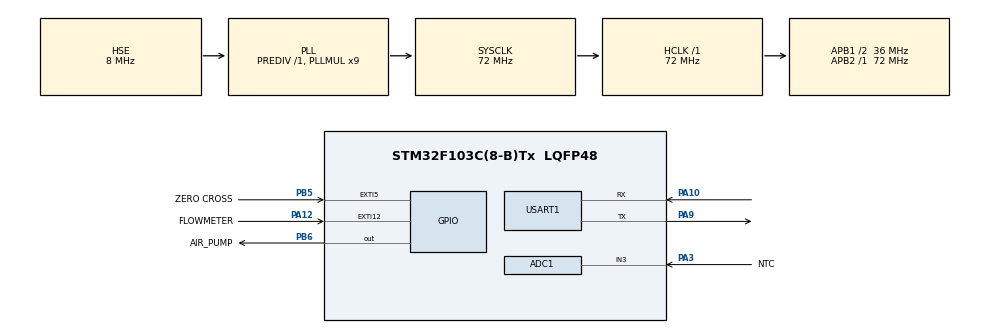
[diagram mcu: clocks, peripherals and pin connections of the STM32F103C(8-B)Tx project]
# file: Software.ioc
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ADC1.Channel-1\#ChannelRegularConversion=ADC_CHANNEL_3
ADC1.ContinuousConvMode=ENABLE
ADC1.NbrOfConversionFlag=1
ADC1.Rank-1\#ChannelRegularConversion=1
ADC1.SamplingTime-1\#ChannelRegularConversion=ADC_SAMPLETIME_1CYCLE_5
ADC1.master=1
Mcu.Family=STM32F1
Mcu.Name=STM32F103C(8-B)Tx
Mcu.Package=LQFP48
NVIC.ADC1_2_IRQn=true\:0\:0\:false\:false\:true\:true\:true
NVIC.EXTI9_5_IRQn=true\:0\:0\:false\:false\:true\:true\:true
NVIC.PriorityGroup=NVIC_PRIORITYGROUP_4
NVIC.TIM2_IRQn=true\:0\:0\:false\:false\:true\:true\:true
PA10.Mode=Asynchronous
PA10.Signal=USART1_RX
PA12.GPIO_Label=FLOWMETER
PA12.Signal=GPXTI12
PA13.Mode=Serial_Wire
PA13.Signal=SYS_JTMS-SWDIO
PA14.Mode=Serial_Wire
PA14.Signal=SYS_JTCK-SWCLK
PA3.GPIO_Label=NTC
PA3.Signal=ADCx_IN3
PA9.Mode=Asynchronous
PA9.Signal=USART1_TX
PB5.GPIO_Label=ZERO CROSS
PB5.Signal=GPXTI5
PB6.GPIO_Label=AIR_PUMP
PB6.Signal=GPIO_Output
PD0-OSC_IN.Mode=HSE-External-Oscillator
PD0-OSC_IN.Signal=RCC_OSC_IN
PD1-OSC_OUT.Mode=HSE-External-Oscillator
PD1-OSC_OUT.Signal=RCC_OSC_OUT
ProjectManager.HeapSize=0x200
ProjectManager.StackSize=0x400
ProjectManager.TargetToolchain=MDK-ARM V5.27
RCC.ADCPresc=RCC_ADCPCLK2_DIV6
RCC.AHBFreq_Value=72000000
RCC.APB1CLKDivider=RCC_HCLK_DIV2
RCC.APB1Freq_Value=36000000
RCC.APB1TimFreq_Value=72000000
RCC.APB2Freq_Value=72000000
RCC.APB2TimFreq_Value=72000000
RCC.HCLKFreq_Value=72000000
RCC.PLLMUL=RCC_PLL_MUL9
RCC.PLLSourceVirtual=RCC_PLLSOURCE_HSE
RCC.SYSCLKFreq_VALUE=72000000
RCC.SYSCLKSource=RCC_SYSCLKSOURCE_PLLCLK
RCC.USBFreq_Value=72000000
SH.ADCx_IN3.0=ADC1_IN3,IN3
TIM1.Period=65535
TIM1.Prescaler=7200-1 
TIM2.Period=1000
TIM2.Prescaler=7200
USART1.VirtualMode=VM_ASYNC
VP_TIM1_VS_ClockSourceINT.Mode=Internal
VP_TIM2_VS_ClockSourceINT.Mode=Internal
board=custom

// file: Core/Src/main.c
/* USER CODE BEGIN Header */
/**
  ******************************************************************************
  * @file           : main.c
  * @brief          : Main program body
  ******************************************************************************
  * @attention
  *
  * <h2><center>&copy; Copyright (c) 2022 STMicroelectronics.
  * All rights reserved.</center></h2>
  *
  * This software component is licensed by ST under BSD 3-Clause license,
  * the "License"; You may not use this file except in compliance with the
  * License. You may obtain a copy of the License at:
  *                        opensource.org/licenses/BSD-3-Clause
  *
  ******************************************************************************
  */
/* USER CODE END Header */
#include "main.h"

/* USER CODE BEGIN Includes */
#include "st7735.h"
#include "Control.h"
#include "NTC.h"
/* USER CODE END Includes */

ADC_HandleTypeDef hadc1;

TIM_HandleTypeDef htim1;
TIM_HandleTypeDef htim2;

UART_HandleTypeDef huart1;

void SystemClock_Config(void);
static void MX_GPIO_Init(void);
static void MX_ADC1_Init(void);
static void MX_TIM1_Init(void);
static void MX_TIM2_Init(void);
static void MX_USART1_UART_Init(void);

/* USER CODE BEGIN 0 */

uint32_t ADC_VAL;

//void HAL_ADC_ConvCpltCallback(ADC_HandleTypeDef* hadc)
//{
//   adc_val = HAL_ADC_GetValue(&hadc1);
//	 res = (adc_val * 47) / (4095 - adc_val);
//   HAL_ADC_Start_IT (&hadc1);
//}
/* USER CODE END 0 */

int main(void)
{

  /* MCU Configuration--------------------------------------------------------*/

  /* Reset of all peripherals, Initializes the Flash interface and the Systick. */
  HAL_Init();

  /* Configure the system clock */
  SystemClock_Config();

  /* Initialize all configured peripherals */
  MX_GPIO_Init();
  MX_ADC1_Init();
  MX_TIM1_Init();
  MX_TIM2_Init();
  MX_USART1_UART_Init();
  /* USER CODE BEGIN 2 */
	ST7735_Init();
	HAL_TIM_Base_Start(&htim1);
	HAL_TIM_Base_Start_IT(&htim2);
  HAL_ADC_Start_IT (&hadc1);
  /* USER CODE END 2 */

  /* Infinite loop */
  /* USER CODE BEGIN WHILE */
  while (1)
  {
		  HAL_GPIO_WritePin(GPIOB, GPIO_PIN_6, GPIO_PIN_SET);
      HAL_Delay(2000);
      // LED OFF
      HAL_GPIO_WritePin(GPIOB, GPIO_PIN_6, GPIO_PIN_RESET);
      HAL_Delay(2000);
    /* USER CODE END WHILE */

  }
}

void SystemClock_Config(void)
{
  RCC_OscInitTypeDef RCC_OscInitStruct = {0};
  RCC_ClkInitTypeDef RCC_ClkInitStruct = {0};
  RCC_PeriphCLKInitTypeDef PeriphClkInit = {0};

  /** Initializes the RCC Oscillators according to the specified parameters
  * in the RCC_OscInitTypeDef structure.
  */
  RCC_OscInitStruct.OscillatorType = RCC_OSCILLATORTYPE_HSE;
  RCC_OscInitStruct.HSEState = RCC_HSE_ON;
  RCC_OscInitStruct.HSEPredivValue = RCC_HSE_PREDIV_DIV1;
  RCC_OscInitStruct.HSIState = RCC_HSI_ON;
  RCC_OscInitStruct.PLL.PLLState = RCC_PLL_ON;
  RCC_OscInitStruct.PLL.PLLSource = RCC_PLLSOURCE_HSE;
  RCC_OscInitStruct.PLL.PLLMUL = RCC_PLL_MUL9;
  if (HAL_RCC_OscConfig(&RCC_OscInitStruct) != HAL_OK)
  {
    Error_Handler();
  }
  /** Initializes the CPU, AHB and APB buses clocks
  */
  RCC_ClkInitStruct.ClockType = RCC_CLOCKTYPE_HCLK|RCC_CLOCKTYPE_SYSCLK
                              |RCC_CLOCKTYPE_PCLK1|RCC_CLOCKTYPE_PCLK2;
  RCC_ClkInitStruct.SYSCLKSource = RCC_SYSCLKSOURCE_PLLCLK;
  RCC_ClkInitStruct.AHBCLKDivider = RCC_SYSCLK_DIV1;
  RCC_ClkInitStruct.APB1CLKDivider = RCC_HCLK_DIV2;
  RCC_ClkInitStruct.APB2CLKDivider = RCC_HCLK_DIV1;

  if (HAL_RCC_ClockConfig(&RCC_ClkInitStruct, FLASH_LATENCY_2) != HAL_OK)
  {
    Error_Handler();
  }
  PeriphClkInit.PeriphClockSelection = RCC_PERIPHCLK_ADC;
  PeriphClkInit.AdcClockSelection = RCC_ADCPCLK2_DIV6;
  if (HAL_RCCEx_PeriphCLKConfig(&PeriphClkInit) != HAL_OK)
  {
    Error_Handler();
  }
}

static void MX_ADC1_Init(void)
{

  ADC_ChannelConfTypeDef sConfig = {0};

  /** Common config
  */
  hadc1.Instance = ADC1;
  hadc1.Init.ScanConvMode = ADC_SCAN_DISABLE;
  hadc1.Init.ContinuousConvMode = ENABLE;
  hadc1.Init.DiscontinuousConvMode = DISABLE;
  hadc1.Init.ExternalTrigConv = ADC_SOFTWARE_START;
  hadc1.Init.DataAlign = ADC_DATAALIGN_RIGHT;
  hadc1.Init.NbrOfConversion = 1;
  if (HAL_ADC_Init(&hadc1) != HAL_OK)
  {
    Error_Handler();
  }
  /** Configure Regular Channel
  */
  sConfig.Channel = ADC_CHANNEL_3;
  sConfig.Rank = ADC_REGULAR_RANK_1;
  sConfig.SamplingTime = ADC_SAMPLETIME_1CYCLE_5;
  if (HAL_ADC_ConfigChannel(&hadc1, &sConfig) != HAL_OK)
  {
    Error_Handler();
  }

}

static void MX_TIM1_Init(void)
{

  TIM_ClockConfigTypeDef sClockSourceConfig = {0};
  TIM_MasterConfigTypeDef sMasterConfig = {0};

  htim1.Instance = TIM1;
  htim1.Init.Prescaler = 7200-1 ;
  htim1.Init.CounterMode = TIM_COUNTERMODE_UP;
  htim1.Init.Period = 65535;
  htim1.Init.ClockDivision = TIM_CLOCKDIVISION_DIV1;
  htim1.Init.RepetitionCounter = 0;
  htim1.Init.AutoReloadPreload = TIM_AUTORELOAD_PRELOAD_DISABLE;
  if (HAL_TIM_Base_Init(&htim1) != HAL_OK)
  {
    Error_Handler();
  }
  sClockSourceConfig.ClockSource = TIM_CLOCKSOURCE_INTERNAL;
  if (HAL_TIM_ConfigClockSource(&htim1, &sClockSourceConfig) != HAL_OK)
  {
    Error_Handler();
  }
  sMasterConfig.MasterOutputTrigger = TIM_TRGO_RESET;
  sMasterConfig.MasterSlaveMode = TIM_MASTERSLAVEMODE_DISABLE;
  if (HAL_TIMEx_MasterConfigSynchronization(&htim1, &sMasterConfig) != HAL_OK)
  {
    Error_Handler();
  }

}

static void MX_TIM2_Init(void)
{

  TIM_ClockConfigTypeDef sClockSourceConfig = {0};
  TIM_MasterConfigTypeDef sMasterConfig = {0};

  htim2.Instance = TIM2;
  htim2.Init.Prescaler = 7200;
  htim2.Init.CounterMode = TIM_COUNTERMODE_UP;
  htim2.Init.Period = 1000;
  htim2.Init.ClockDivision = TIM_CLOCKDIVISION_DIV1;
  htim2.Init.AutoReloadPreload = TIM_AUTORELOAD_PRELOAD_DISABLE;
  if (HAL_TIM_Base_Init(&htim2) != HAL_OK)
  {
    Error_Handler();
  }
  sClockSourceConfig.ClockSource = TIM_CLOCKSOURCE_INTERNAL;
  if (HAL_TIM_ConfigClockSource(&htim2, &sClockSourceConfig) != HAL_OK)
  {
    Error_Handler();
  }
  sMasterConfig.MasterOutputTrigger = TIM_TRGO_RESET;
  sMasterConfig.MasterSlaveMode = TIM_MASTERSLAVEMODE_DISABLE;
  if (HAL_TIMEx_MasterConfigSynchronization(&htim2, &sMasterConfig) != HAL_OK)
  {
    Error_Handler();
  }

}

static void MX_USART1_UART_Init(void)
{

  huart1.Instance = USART1;
  huart1.Init.BaudRate = 115200;
  huart1.Init.WordLength = UART_WORDLENGTH_8B;
  huart1.Init.StopBits = UART_STOPBITS_1;
  huart1.Init.Parity = UART_PARITY_NONE;
  huart1.Init.Mode = UART_MODE_TX_RX;
  huart1.Init.HwFlowCtl = UART_HWCONTROL_NONE;
  huart1.Init.OverSampling = UART_OVERSAMPLING_16;
  if (HAL_UART_Init(&huart1) != HAL_OK)
  {
    Error_Handler();
  }

}

static void MX_GPIO_Init(void)
{
  GPIO_InitTypeDef GPIO_InitStruct = {0};

  /* GPIO Ports Clock Enable */
  __HAL_RCC_GPIOD_CLK_ENABLE();
  __HAL_RCC_GPIOA_CLK_ENABLE();
  __HAL_RCC_GPIOB_CLK_ENABLE();

  /*Configure GPIO pin Output Level */
  HAL_GPIO_WritePin(AIR_PUMP_GPIO_Port, AIR_PUMP_Pin, GPIO_PIN_RESET);

  /*Configure GPIO pin : FLOWMETER_Pin */
  GPIO_InitStruct.Pin = FLOWMETER_Pin;
  GPIO_InitStruct.Mode = GPIO_MODE_IT_RISING;
  GPIO_InitStruct.Pull = GPIO_NOPULL;
  HAL_GPIO_Init(FLOWMETER_GPIO_Port, &GPIO_InitStruct);

  /*Configure GPIO pin : ZERO_CROSS_Pin */
  GPIO_InitStruct.Pin = ZERO_CROSS_Pin;
  GPIO_InitStruct.Mode = GPIO_MODE_IT_RISING;
  GPIO_InitStruct.Pull = GPIO_NOPULL;
  HAL_GPIO_Init(ZERO_CROSS_GPIO_Port, &GPIO_InitStruct);

  /*Configure GPIO pin : AIR_PUMP_Pin */
  GPIO_InitStruct.Pin = AIR_PUMP_Pin;
  GPIO_InitStruct.Mode = GPIO_MODE_OUTPUT_PP;
  GPIO_InitStruct.Pull = GPIO_NOPULL;
  GPIO_InitStruct.Speed = GPIO_SPEED_FREQ_LOW;
  HAL_GPIO_Init(AIR_PUMP_GPIO_Port, &GPIO_InitStruct);

  /* EXTI interrupt init*/
  HAL_NVIC_SetPriority(EXTI9_5_IRQn, 0, 0);
  HAL_NVIC_EnableIRQ(EXTI9_5_IRQn);

}

/* USER CODE BEGIN 4 */
void HAL_TIM_PeriodElapsedCallback(TIM_HandleTypeDef *htim)
{
   ADC_VAL = HAL_ADC_GetValue(&hadc1);
}
/* USER CODE END 4 */

void Error_Handler(void)
{
  __disable_irq();
  while (1)
  {
  }
}

/************************ (C) COPYRIGHT STMicroelectronics *****END OF FILE****/
